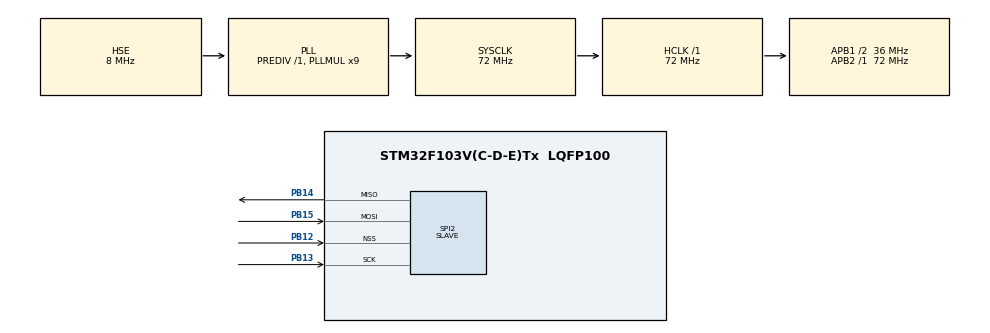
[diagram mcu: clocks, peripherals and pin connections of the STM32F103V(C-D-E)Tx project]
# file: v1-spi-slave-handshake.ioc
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Mcu.Family=STM32F1
Mcu.Name=STM32F103V(C-D-E)Tx
Mcu.Package=LQFP100
NVIC.PriorityGroup=NVIC_PRIORITYGROUP_4
OSC_IN.Mode=HSE-External-Oscillator
OSC_IN.Signal=RCC_OSC_IN
OSC_OUT.Mode=HSE-External-Oscillator
OSC_OUT.Signal=RCC_OSC_OUT
PA13.Mode=Serial_Wire
PA13.Signal=SYS_JTMS-SWDIO
PA14.Mode=Serial_Wire
PA14.Signal=SYS_JTCK-SWCLK
PB12.Mode=NSS_Signal_Hard_Input
PB12.Signal=SPI2_NSS
PB13.Mode=Full_Duplex_Slave
PB13.Signal=SPI2_SCK
PB14.Mode=Full_Duplex_Slave
PB14.Signal=SPI2_MISO
PB15.Mode=Full_Duplex_Slave
PB15.Signal=SPI2_MOSI
ProjectManager.HeapSize=0x200
ProjectManager.StackSize=0x400
ProjectManager.TargetToolchain=MDK-ARM V5.32
RCC.AHBFreq_Value=72000000
RCC.APB1CLKDivider=RCC_HCLK_DIV2
RCC.APB1Freq_Value=36000000
RCC.APB1TimFreq_Value=72000000
RCC.APB2Freq_Value=72000000
RCC.APB2TimFreq_Value=72000000
RCC.HCLKFreq_Value=72000000
RCC.PLLMUL=RCC_PLL_MUL9
RCC.PLLSourceVirtual=RCC_PLLSOURCE_HSE
RCC.SYSCLKFreq_VALUE=72000000
RCC.SYSCLKSource=RCC_SYSCLKSOURCE_PLLCLK
RCC.USBFreq_Value=72000000
SPI2.Direction=SPI_DIRECTION_2LINES
SPI2.Mode=SPI_MODE_SLAVE
SPI2.VirtualNSS=VM_NSSHARD
SPI2.VirtualType=VM_SLAVE
board=custom

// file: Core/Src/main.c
/* USER CODE BEGIN Header */
/**
  ******************************************************************************
  * @file           : main.c
  * @brief          : Main program body
  ******************************************************************************
  * @attention
  *
  * Copyright (c) 2026 STMicroelectronics.
  * All rights reserved.
  *
  * This software is licensed under terms that can be found in the LICENSE file
  * in the root directory of this software component.
  * If no LICENSE file comes with this software, it is provided AS-IS.
  *
  ******************************************************************************
  */
/* USER CODE END Header */
#include "main.h"
#include "spi.h"
#include "gpio.h"

void SystemClock_Config(void);
/* USER CODE BEGIN PFP */

void SPI_HandleTransaction(void);
/* USER CODE END PFP */

int main(void)
{

  /* MCU Configuration--------------------------------------------------------*/

  /* Reset of all peripherals, Initializes the Flash interface and the Systick. */
  HAL_Init();

  /* Configure the system clock */
  SystemClock_Config();

  /* Initialize all configured peripherals */
  MX_GPIO_Init();
  MX_SPI2_Init();

  /* Infinite loop */
  while (1)
  {
		SPI_HandleTransaction();
  }
}

void SystemClock_Config(void)
{
  RCC_OscInitTypeDef RCC_OscInitStruct = {0};
  RCC_ClkInitTypeDef RCC_ClkInitStruct = {0};

  /** Initializes the RCC Oscillators according to the specified parameters
  * in the RCC_OscInitTypeDef structure.
  */
  RCC_OscInitStruct.OscillatorType = RCC_OSCILLATORTYPE_HSE;
  RCC_OscInitStruct.HSEState = RCC_HSE_ON;
  RCC_OscInitStruct.HSEPredivValue = RCC_HSE_PREDIV_DIV1;
  RCC_OscInitStruct.HSIState = RCC_HSI_ON;
  RCC_OscInitStruct.PLL.PLLState = RCC_PLL_ON;
  RCC_OscInitStruct.PLL.PLLSource = RCC_PLLSOURCE_HSE;
  RCC_OscInitStruct.PLL.PLLMUL = RCC_PLL_MUL9;
  if (HAL_RCC_OscConfig(&RCC_OscInitStruct) != HAL_OK)
  {
    Error_Handler();
  }

  /** Initializes the CPU, AHB and APB buses clocks
  */
  RCC_ClkInitStruct.ClockType = RCC_CLOCKTYPE_HCLK|RCC_CLOCKTYPE_SYSCLK
                              |RCC_CLOCKTYPE_PCLK1|RCC_CLOCKTYPE_PCLK2;
  RCC_ClkInitStruct.SYSCLKSource = RCC_SYSCLKSOURCE_PLLCLK;
  RCC_ClkInitStruct.AHBCLKDivider = RCC_SYSCLK_DIV1;
  RCC_ClkInitStruct.APB1CLKDivider = RCC_HCLK_DIV2;
  RCC_ClkInitStruct.APB2CLKDivider = RCC_HCLK_DIV1;

  if (HAL_RCC_ClockConfig(&RCC_ClkInitStruct, FLASH_LATENCY_2) != HAL_OK)
  {
    Error_Handler();
  }
}

/* USER CODE BEGIN 4 */

// V1.1: Minimal SPI slave handshake
// Protocol: Pi sends 1-byte command →
// MCU returns the corresponding register value
// Command 0x00 = Read DEVICE_ID (returns 4-byte magic value)
// Other commands = Return 0xFF (invalid)

#define DEVICE_ID_MAGIC 0xAC00ACC0

static uint8_t rx_buf[8];
static uint8_t tx_buf[8];

void SPI_HandleTransaction(void)
{
    // Blocking receive of 5 bytes: 1-byte command + 4 dummy bytes
    // (Pi reads back 5 bytes)

    // Simultaneously transmit 5 bytes: 1-byte status + 4-byte data

    tx_buf[0] = 0xA5;  // Fixed status byte for easy identification during debugging
    // big-endian
    tx_buf[1] = (DEVICE_ID_MAGIC >> 24) & 0xFF;
    tx_buf[2] = (DEVICE_ID_MAGIC >> 16) & 0xFF;
    tx_buf[3] = (DEVICE_ID_MAGIC >> 8) & 0xFF;
    tx_buf[4] = DEVICE_ID_MAGIC & 0xFF;

    HAL_SPI_TransmitReceive(&hspi2, tx_buf, rx_buf, 5, HAL_MAX_DELAY);
}

/* USER CODE END 4 */

void Error_Handler(void)
{
  __disable_irq();
  while (1)
  {
  }
}
